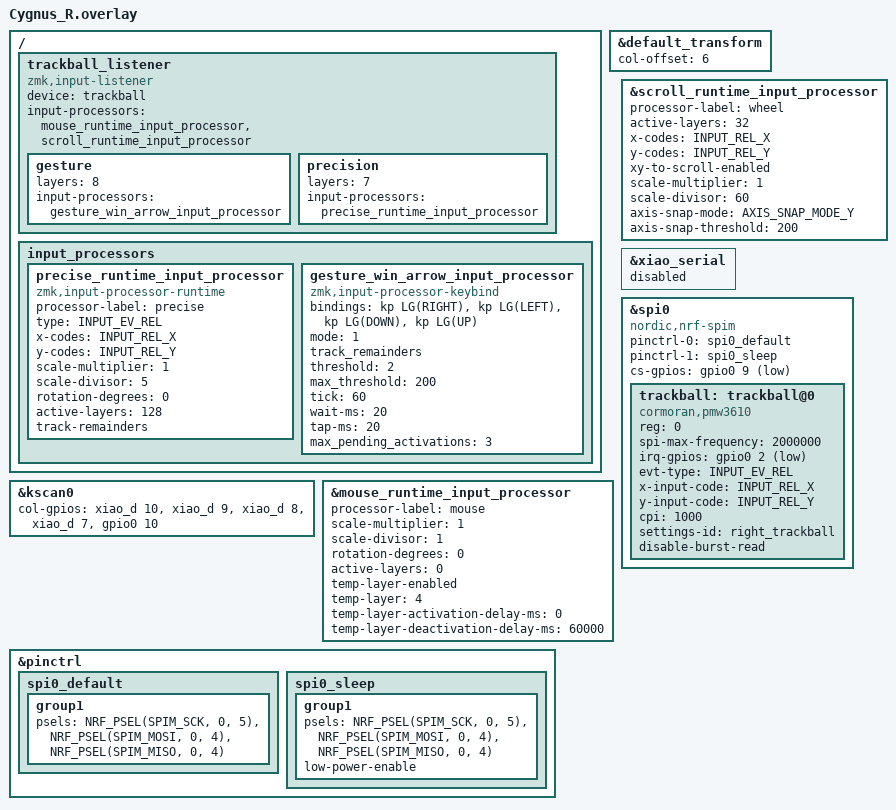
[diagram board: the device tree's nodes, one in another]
#include "Cygnus.dtsi"
#include <zephyr/dt-bindings/input/input-event-codes.h>
#include <input/processors.dtsi>
#include <input/processors/runtime-input-processor.dtsi>
#include <dt-bindings/zmk/runtime_input_processor.h>
#include <dt-bindings/zmk/keys.h>

&default_transform {
    col-offset = <6>;
};

&kscan0 {
        col-gpios
            = <&xiao_d 10 GPIO_ACTIVE_HIGH>
            , <&xiao_d 9 GPIO_ACTIVE_HIGH> 
            , <&xiao_d 8 GPIO_ACTIVE_HIGH> 
            , <&xiao_d 7 GPIO_ACTIVE_HIGH> 
            , <&gpio0 10 GPIO_ACTIVE_HIGH>
            ;
};

/ {
    trackball_listener {
        compatible = "zmk,input-listener";
        device = <&trackball>;
        input-processors = <&mouse_runtime_input_processor &scroll_runtime_input_processor>;

        gesture {
            layers = <8>;
            input-processors = <&gesture_win_arrow_input_processor>;
        };

        precision {
            layers = <7>;
            input-processors = <&precise_runtime_input_processor>;
        };
    };

    input_processors {
        precise_runtime_input_processor: precise_runtime_input_processor {
            compatible = "zmk,input-processor-runtime";
            processor-label = "precise";
            type = <INPUT_EV_REL>;
            x-codes = <INPUT_REL_X>;
            y-codes = <INPUT_REL_Y>;
            scale-multiplier = <1>;
            scale-divisor = <5>;
            rotation-degrees = <0>;
            active-layers = <128>;
            track-remainders;
            #input-processor-cells = <0>;
        };

        gesture_win_arrow_input_processor: gesture_win_arrow_input_processor {
            compatible = "zmk,input-processor-keybind";
            #input-processor-cells = <0>;
            bindings = <&kp LG(RIGHT)>,
                       <&kp LG(LEFT)>,
                       <&kp LG(DOWN)>,
                       <&kp LG(UP)>;
            mode = <1>;
            track_remainders;
            threshold = <2>;
            max_threshold = <200>;
            tick = <60>;
            wait-ms = <20>;
            tap-ms = <20>;
            max_pending_activations = <3>;
        };
    };
};

&mouse_runtime_input_processor {
    processor-label = "mouse";

    /* Preserve the existing auto-mouse behavior while making it editable. */
    scale-multiplier = <1>;
    scale-divisor = <1>;
    rotation-degrees = <0>;
    active-layers = <0>;
    temp-layer-enabled;
    temp-layer = <4>;
    temp-layer-activation-delay-ms = <0>;
    temp-layer-deactivation-delay-ms = <60000>;
};

&scroll_runtime_input_processor {
    processor-label = "wheel";

    /* Use the trackball's X/Y movement as scroll only on Layer 5. */
    active-layers = <32>;
    x-codes = <INPUT_REL_X>;
    y-codes = <INPUT_REL_Y>;
    xy-to-scroll-enabled;
    scale-multiplier = <1>;
    scale-divisor = <60>;
    axis-snap-mode = <AXIS_SNAP_MODE_Y>;
    axis-snap-threshold = <200>;
};

&pinctrl {
    spi0_default: spi0_default {
        group1 {
            psels = <NRF_PSEL(SPIM_SCK, 0, 5)>,
                <NRF_PSEL(SPIM_MOSI, 0, 4)>,
                <NRF_PSEL(SPIM_MISO, 0, 4)>;
        };
    };

    spi0_sleep: spi0_sleep {
        group1 {
            psels = <NRF_PSEL(SPIM_SCK, 0, 5)>,
                <NRF_PSEL(SPIM_MOSI, 0, 4)>,
                <NRF_PSEL(SPIM_MISO, 0, 4)>;
            low-power-enable;
        };
    };
};

&xiao_serial { status = "disabled"; };

&spi0 {
    status = "okay";
    compatible = "nordic,nrf-spim";
    pinctrl-0 = <&spi0_default>;
    pinctrl-1 = <&spi0_sleep>;
    pinctrl-names = "default", "sleep";
    cs-gpios = <&gpio0 9 GPIO_ACTIVE_LOW>;

    trackball: trackball@0 {
        status = "okay";
        compatible = "cormoran,pmw3610";
        reg = <0>;
        spi-max-frequency = <2000000>;
        irq-gpios = <&gpio0 2 (GPIO_ACTIVE_LOW | GPIO_PULL_UP)>;
        evt-type = <INPUT_EV_REL>;
        x-input-code = <INPUT_REL_X>;
        y-input-code = <INPUT_REL_Y>;
        cpi = <1000>;
        settings-id = "right_trackball";
        disable-burst-read;
    };
};
